# STM32U083xx register map
File version: 1.0
Registers are 32-bit, read-write, reset 0x0 unless marked. A register's access mark holds for its fields unless they carry their own. Offsets are from the block's base; [hi:lo] are bit positions; {n}, {i} and the like mark numbered series; 'fields as' and 'values as' point back to an identical list.

## SYSCFG — System configuration controller
Base 0x40010000
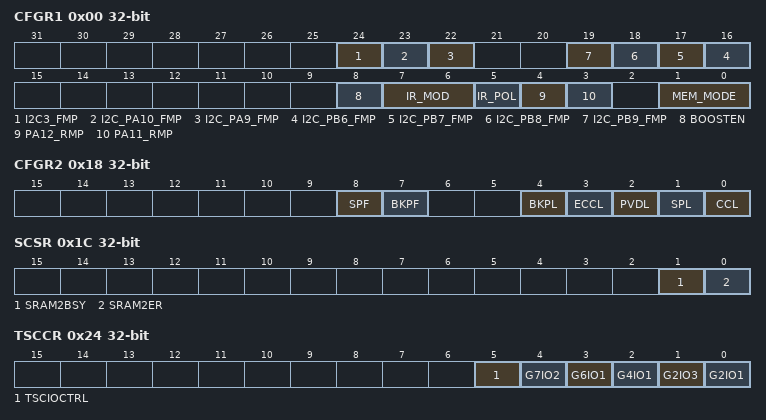
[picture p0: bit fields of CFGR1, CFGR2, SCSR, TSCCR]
0x00 CFGR1 — SYSCFG Control register
  [24] I2C3_FMP — Enable Fast Mode Plus for I2C3
  [23] I2C_PA10_FMP — Enable Fast Mode Plus on PA10
  [22] I2C_PA9_FMP — Enable Fast Mode Plus on PA9
  [n+10] I2C_PB{n}_FMP (n=6..9) — I2C PB{n} Fast mode plus
  [8] BOOSTEN — I/O analog switch voltage booster enable
  [7:6] IR_MOD — IRDA Modulation Envelope signal source selection
    0=TIM16 (00: Timer16 is selected as IRDA Modulation envelope source); 1=USART1 (01: USART1 is selected as IRDA Modulation envelope source); 2=USART2 (10: USART2 is selected as IRDA Modulation envelope source)
  [5] IR_POL — IROut Polarity Selection
    1=INVERTED (1: Output of IRDA (IROut) inverted); 0=NOT_INVERTED (0: Output of IRDA (IROut) not inverted)
  [4] PA12_RMP — PA12 Remap
  [3] PA11_RMP — PA11 Remap
  [1:0] MEM_MODE — SYSCFG_Memory Remap Config
    0=FLASH (Main Flash memory mapped at 0x00000000); 1=SYSTEMFLASH (System Flash memory mapped at 0x00000000); 3=SRAM (Embedded SRAM mapped at 0x00000000)
0x18 CFGR2 — SYSCFG Class B register
  [8] SPF — Saves the occurrence of the SRAM Parity Error
  [7] BKPF — Saves the occurrence of the BackUpSRAM Parity Error
  [4] BKPL — Enables and locks the BackUp SRAM Parity error signal with TIMERs Break Input
  [3] ECCL — Enables and locks the FLASH ECC error with TIMERs Break Input
  [2] PVDL — Enables and locks the PVD connection with TIMERs Break Input
  [1] SPL — Enables and locks the SRAM Parity error signal with TIMERs Break Input
  [0] CCL — Enables and locks the LOCKUP (Hardfault) output of CortexM0 with Break Input
0x1C SCSR — SYSCFG Backup Sram Erase Register
  [1] SRAM2BSY — BackUpSRAM Erase Ongoing Status Flag
  [0] SRAM2ER — Starts a hardware BackUpSRAM erase operation
0x20 SKR — SYSCFG Backup Sram Key Register
  [7:0] KEY — Write BackUpSRAM Key for software erase
0x24 TSCCR — SYSCFG TSC Comp Register
  [5] TSCIOCTRL — Program Comparator mode (programmed via alternate function)
    0=REG (I/O configured through the corresponding control register); 1=ANALOG (I/O configured as analog when TSC AF is activated)
  [4] G7IO2 — Enable the comparator mode with the IO2 of Group7 (PA9 on INPLUS of COMP1)
  [3] G6IO1 — Enable the comparator mode with the IO1 of Group6 (PD10 on INPLUS of COMP2)
  [2] G4IO1 — Enable the comparator mode with the IO1 of Group4 (PC6 on INPLUS of COMP1)
  [1] G2IO3 — Enable the comparator mode with the IO3 of Group2 (PB6 on INPLUS of COMP2)
  [0] G2IO1 — Enable the comparator mode with the IO1 of Group2 (PB4 on INPLUS of COMP2)
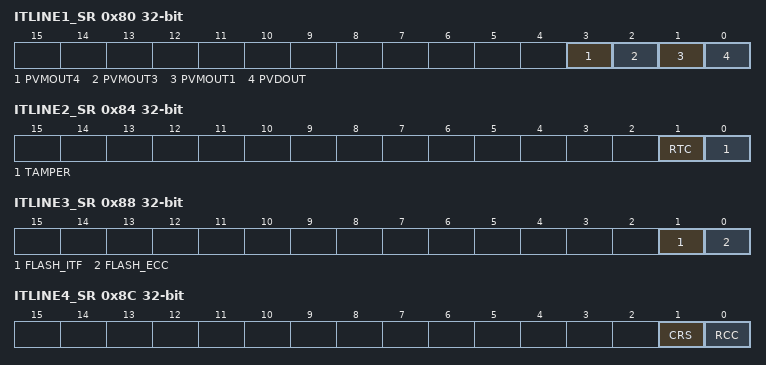
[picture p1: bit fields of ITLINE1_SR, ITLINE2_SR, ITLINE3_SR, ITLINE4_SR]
0x80 ITLINE1_SR — SYSCFG configuration IT_LINE register
  [3] PVMOUT4 — VDDADC interrupt
  [2] PVMOUT3 — VDDADC interrupt
  [1] PVMOUT1 — VDDUSB interrupt
  [0] PVDOUT — PVDOUT interrupt
0x84 ITLINE2_SR — SYSCFG configuration IT_LINE register
  [1] RTC — RTC interrupt
  [0] TAMPER — TAMPER interrupt
0x88 ITLINE3_SR — SYSCFG configuration IT_LINE register
  [1] FLASH_ITF — FLASH ITF interrupt
  [0] FLASH_ECC — FLASH ECC interrupt
0x8C ITLINE4_SR — SYSCFG configuration IT_LINE register
  [1] CRS — CRS interrupt
  [0] RCC — RCC interrupt
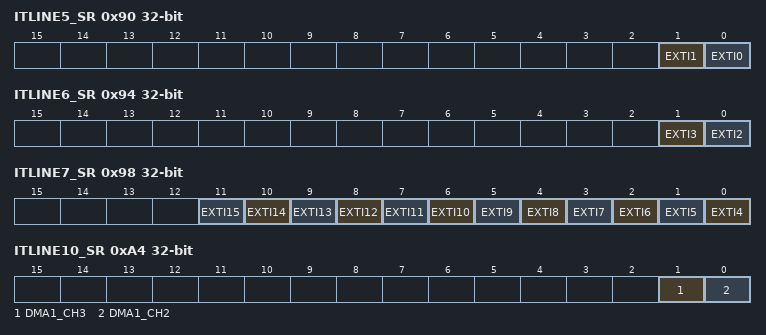
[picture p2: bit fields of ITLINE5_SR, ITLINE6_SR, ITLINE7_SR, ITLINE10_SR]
0x90 ITLINE5_SR — SYSCFG configuration IT_LINE register
  [1] EXTI1 — External Interrupt 1
  [0] EXTI0 — External Interrupt 0
0x94 ITLINE6_SR — SYSCFG configuration IT_LINE register
  [1] EXTI3 — External Interrupt 3
  [0] EXTI2 — External Interrupt 2
0x98 ITLINE7_SR — SYSCFG configuration IT_LINE register
  [n-4] EXTI{n} (n=4..15) — External Interrupt {n}
0x9C ITLINE8_SR — SYSCFG configuration IT_LINE register
  [0] USBFS — USBFS Interrupt
0xA0 ITLINE9_SR — SYSCFG configuration IT_LINE register
  [0] DMA1_CH1 — DMA1 Channel 1 Interrupt
0xA4 ITLINE10_SR — SYSCFG configuration IT_LINE register
  [1] DMA1_CH3 — DMA1 Channel 3 Interrupt
  [0] DMA1_CH2 — DMA1 Channel 2 Interrupt
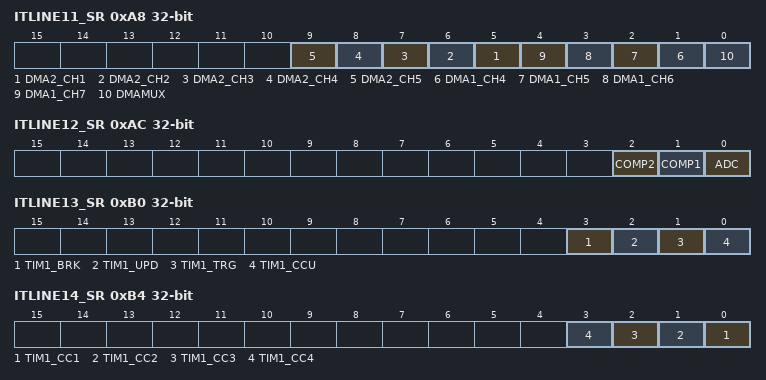
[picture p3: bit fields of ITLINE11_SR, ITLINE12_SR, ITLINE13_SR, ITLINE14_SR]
0xA8 ITLINE11_SR — SYSCFG configuration IT_LINE register
  [n+4] DMA2_CH{n} (n=1..5) — DMA1 Channel {n+7} Interrupt
  [n-3] DMA1_CH{n} (n=4..7) — DMA1 Channel {n} Interrupt
  [0] DMAMUX — DMAMUX Interrupt
0xAC ITLINE12_SR — SYSCFG configuration IT_LINE register
  [2] COMP2 — COMP2 Interrupt -> exti[18]
  [1] COMP1 — COMP1 Interrupt -> exti[17]
  [0] ADC — ADC Interrupt
0xB0 ITLINE13_SR — SYSCFG configuration IT_LINE register
  [3] TIM1_BRK — TIM1 BRK Interrupt
  [2] TIM1_UPD — TIM1 UPD Interrupt
  [1] TIM1_TRG — TIM1 TRG Interrupt
  [0] TIM1_CCU — TIM1 CCU Interrupt
0xB4 ITLINE14_SR — SYSCFG configuration IT_LINE register
  [n-1] TIM1_CC{n} (n=1..4) — TIM1 CC{n} Interrupt
0xB8 ITLINE15_SR — SYSCFG configuration IT_LINE register
  [0] TIM2 — TIM2 GLB Interrupt
0xBC ITLINE16_SR — SYSCFG configuration IT_LINE register
  [0] TIM3 — TIM3 GLB Interrupt
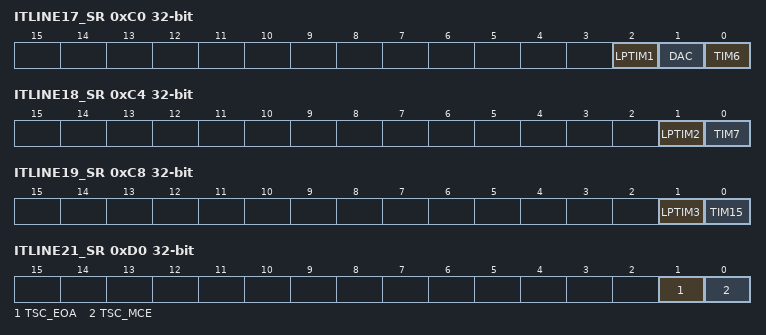
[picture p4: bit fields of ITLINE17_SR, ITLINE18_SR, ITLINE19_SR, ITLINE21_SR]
0xC0 ITLINE17_SR — SYSCFG configuration IT_LINE register
  [2] LPTIM1 — LPTIM1 -> exti[24] Interrupt
  [1] DAC — DAC Interrupt
  [0] TIM6 — TIM6 GLB Interrupt
0xC4 ITLINE18_SR — SYSCFG configuration IT_LINE register
  [1] LPTIM2 — LPTIM2 -> exti[25] Interrupt
  [0] TIM7 — TIM7 GLB Interrupt
0xC8 ITLINE19_SR — SYSCFG configuration IT_LINE register
  [1] LPTIM3 — LPTIM3 GLB Interrupt -> exti [26]
  [0] TIM15 — TIM15 GLB Interrupt
0xCC ITLINE20_SR — SYSCFG configuration IT_LINE register
  [0] TIM16 — TIM16 GLB Interrupt
0xD0 ITLINE21_SR — SYSCFG configuration IT_LINE register
  [1] TSC_EOA — TSC_MCE Interrupt
  [0] TSC_MCE — TSC_MCE Interrupt
0xD4 ITLINE22_SR — SYSCFG configuration IT_LINE register
  [0] LCD — LCD GLB Interrupt
0xD8 ITLINE23_SR — SYSCFG configuration IT_LINE register
  [0] I2C1 — I2C1 GLB Interrupt
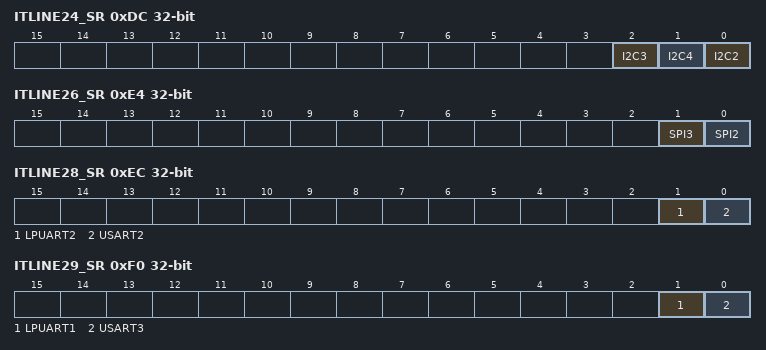
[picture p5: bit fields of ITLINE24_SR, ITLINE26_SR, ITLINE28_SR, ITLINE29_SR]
0xDC ITLINE24_SR — SYSCFG configuration IT_LINE register
  [2] I2C3 — I2C3 GLB Interrupt -> exti[23]
  [1] I2C4 — I2C3 GLB Interrupt
  [0] I2C2 — I2C2 GLB Interrupt
0xE0 ITLINE25_SR — SYSCFG configuration IT_LINE register
  [0] SPI1 — SPI1 Interrupt
0xE4 ITLINE26_SR — SYSCFG configuration IT_LINE register
  [1] SPI3 — SPI3 Interrupt
  [0] SPI2 — SPI2 Interrupt
0xE8 ITLINE27_SR — SYSCFG configuration IT_LINE register
  [0] USART1 — USART1 GLB Interrupt
0xEC ITLINE28_SR — SYSCFG configuration IT_LINE register
  [1] LPUART2 — LPUART2 GLB Interrupt -> exti[31]
  [0] USART2 — USART2 GLB Interrupt
0xF0 ITLINE29_SR — SYSCFG configuration IT_LINE register
  [1] LPUART1 — LPUART1 GLB Interrupt -> exti[30]
  [0] USART3 — USART3 GLB Interrupt
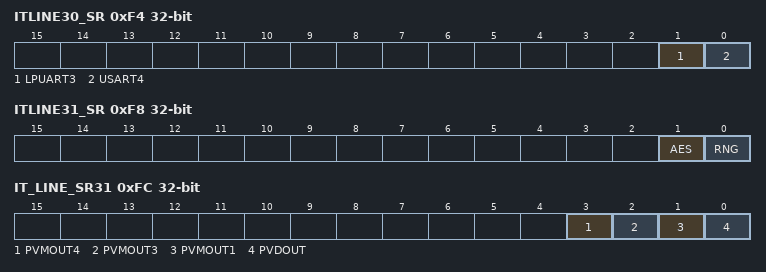
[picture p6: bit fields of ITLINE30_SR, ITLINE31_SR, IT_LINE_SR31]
0xF4 ITLINE30_SR — SYSCFG configuration IT_LINE register
  [1] LPUART3 — LPUART3 GLB Interrupt
  [0] USART4 — USART4 GLB Interrupt
0xF8 ITLINE31_SR — SYSCFG configuration IT_LINE register
  [1] AES — AES Interrupt
  [0] RNG — RNG Interrupt
0xFC IT_LINE_SR31 — SYSCFG configuration IT_LINE register
  fields as ITLINE1_SR
